# PIC32CX5112MTSH128 register map
Vendor: Microchip Technology; Series: PIC32CXMTSH; File version: 0
CPU: CM4 r0p1, selectable endian, MPU, FPU, 4 interrupt priority bits
Registers are 32-bit, read-write, reset 0x0 unless marked. A register's access mark holds for its fields unless they carry their own. Offsets are from the block's base; [hi:lo] are bit positions.

## ACC — Analog Comparator Controller
Base 0x40028000; register names take the prefix ACC_
0x00 CR wo — Control Register
  [0] SWRST — Software Reset
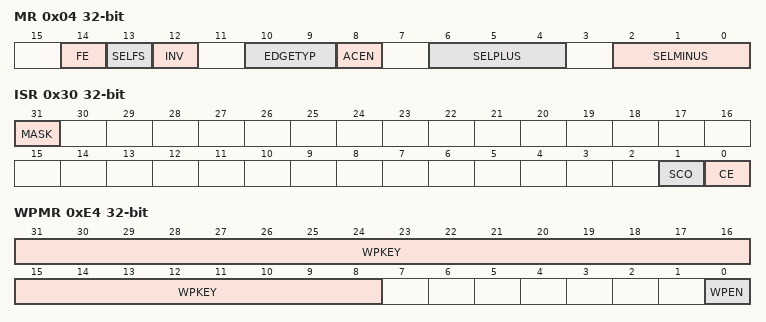
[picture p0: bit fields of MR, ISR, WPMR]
0x04 MR — Mode Register
  [14] FE — Fault Enable
    0=DIS (The FAULT output is tied to 0.); 1=EN (The FAULT output is driven by the signal defined by SELFS.)
  [13] SELFS — Selection Of Fault Source
    0=CE (The CE flag is used to drive the FAULT output.); 1=OUTPUT (The output of the analog comparator flag is used to drive the FAULT output.)
  [12] INV — Invert Comparator Output
    0=DIS (Analog comparator output is directly processed.); 1=EN (Analog comparator output is inverted prior to being processed.)
  [10:9] EDGETYP — Edge Type
    0=RISING (Only rising edge of comparator output); 1=FALLING (Falling edge of comparator output); 2=ANY (Any edge of comparator output)
  [8] ACEN — Analog Comparator Enable
    0=DIS (Analog comparator disabled.); 1=EN (Analog comparator enabled.)
  [6:4] SELPLUS — Selection For Plus Comparator Input
    0=AD0 (Selects AD0); 1=AD1 (Selects AD1); 2=AD2 (Selects AD2); 3=VREFP (Selects VREFP)
  [2:0] SELMINUS — Selection for Minus Comparator Input
    0=AD3 (Selects AD3); 1=AD4 (Selects AD4); 2=VTEMP (Selects VTEMP); 3=VREFTEMP (Selects VREFTEMP)
0x24 IER wo — Interrupt Enable Register
  [0] CE — Comparison Edge
0x28 IDR wo — Interrupt Disable Register
  [0] CE — Comparison Edge
0x2C IMR ro — Interrupt Mask Register
  [0] CE — Comparison Edge
0x30 ISR ro — Interrupt Status Register
  [31] MASK — Flag Mask
  [1] SCO — Synchronized Comparator Output
  [0] CE — Comparison Edge (cleared on read)
0x94 ACR — Analog Control Register
  [0] MSEL — Masking Period Selection
    0=Masks AC output for 16 peripheral clock periods after any write access in ACC_MR or ACC_CR; 1=Masks AC output for 128 peripheral clock periods after any write access in ACC_MR or ACC_CR
0xE4 WPMR — Write Protection Mode Register
  [31:8] WPKEY — Write Protection Key
    0x414343=PASSWD (Writing any other value in this field aborts the write operation of the WPEN bit. Always reads as 0.)
  [0] WPEN — Write Protection Configuration Enable
0xE8 WPSR ro — Write Protection Status Register
  [0] WPVS — Write Protection Violation Status

## CHIPID — Chip Identifier
Base 0x40050200; register names take the prefix CHIPID_
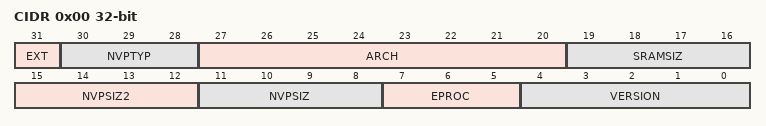
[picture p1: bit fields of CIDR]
0x00 CIDR ro — Chip ID Register
  [31] EXT — Extension Flag
  [30:28] NVPTYP — Nonvolatile Program Memory Type
    0=ROM; 1=ROMLESS (ROMless or on-chip Flash); 2=FLASH (Embedded Flash Memory); 3=ROM_FLASH (ROM and Embedded Flash Memory - NVPSIZ is ROM size - NVPSIZ2 is Flash size); 4=SRAM (SRAM emulating ROM)
  [27:20] ARCH — Architecture Identifier
    195=PIC32CXMTSH128 (Dual Core, Single Phase, High Accuracy (128-lead version)); 197=PIC32CXMTC128 (Dual Core (128-lead version)); 198=PIC32CXMTG64 (Single Core (64-lead version)); 200=PIC32CXMTG128 (Single Core (128-lead version))
  [19:16] SRAMSIZ — Internal SRAM Size
    0=_48K (48 Kbytes); 1=_192K (192 Kbytes); 2=_384K (384 Kbytes); 3=_6K (6 Kbytes); 4=_24K (24 Kbytes); 5=_4K (4 Kbytes); 6=_80K (80 Kbytes); 7=_160K (160 Kbytes); 8=_8K (8 Kbytes); 9=_16K (16 Kbytes); 10=_32K (32 Kbytes); 11=_64K (64 Kbytes); 12=_128K (128 Kbytes); 13=_256K (256 Kbytes); 14=_96K (96 Kbytes); 15=_512K (512 Kbytes)
  [15:12] NVPSIZ2 — Second Nonvolatile Program Memory Size
    0=NONE; 1=_8K (8 Kbytes); 2=_16K (16 Kbytes); 3=_32K (32 Kbytes); 5=_64K (64 Kbytes); 7=_128K (128 Kbytes); 9=_256K (256 Kbytes); 10=_512K (512 Kbytes); 12=_1024K (1024 Kbytes); 14=_2048K (2048 Kbytes)
  [11:8] NVPSIZ — Nonvolatile Program Memory Size
    0=NONE; 1=_8K (8 Kbytes); 2=_16K (16 Kbytes); 3=_32K (32 Kbytes); 5=_64K (64 Kbytes); 7=_128K (128 Kbytes); 8=_160K (160 Kbytes); 9=_256K (256 Kbytes); 10=_512K (512 Kbytes); 12=_1024K (1024 Kbytes); 14=_2048K (2048 Kbytes)
  [7:5] EPROC — Embedded Processor
    0=SAMx7 (Cortex-M7); 1=ARM946ES; 2=ARM7TDMI; 3=CM3 (Cortex-M3); 4=ARM920T; 5=ARM926EJS; 6=CA5 (Cortex-A5); 7=CM4 (Cortex-M4)
  [4:0] VERSION — Version of the Device
0x04 EXID ro — Chip ID Extension Register
  [31:0] EXID — Chip ID Extension
